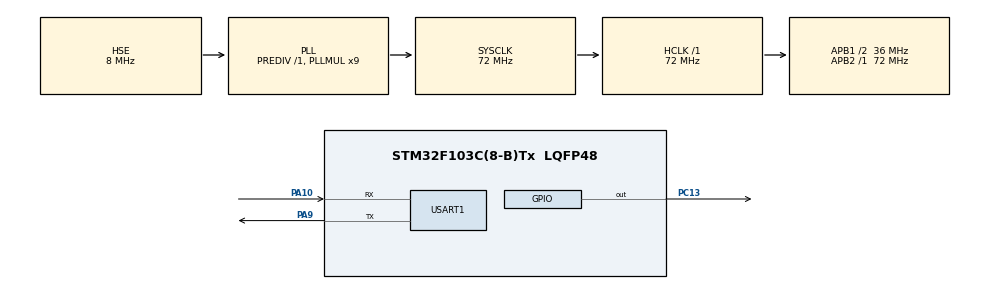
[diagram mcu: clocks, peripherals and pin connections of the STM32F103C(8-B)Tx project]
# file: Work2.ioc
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Mcu.Family=STM32F1
Mcu.Name=STM32F103C(8-B)Tx
Mcu.Package=LQFP48
NVIC.PriorityGroup=NVIC_PRIORITYGROUP_4
NVIC.USART1_IRQn=true\:0\:0\:false\:false\:true\:true\:true\:true
PA10.Mode=Asynchronous
PA10.Signal=USART1_RX
PA13.Mode=Serial_Wire
PA13.Signal=SYS_JTMS-SWDIO
PA14.Mode=Serial_Wire
PA14.Signal=SYS_JTCK-SWCLK
PA9.Mode=Asynchronous
PA9.Signal=USART1_TX
PC13-TAMPER-RTC.PinState=GPIO_PIN_SET
PC13-TAMPER-RTC.Signal=GPIO_Output
PD0-OSC_IN.Mode=HSE-External-Oscillator
PD0-OSC_IN.Signal=RCC_OSC_IN
PD1-OSC_OUT.Mode=HSE-External-Oscillator
PD1-OSC_OUT.Signal=RCC_OSC_OUT
ProjectManager.HeapSize=0x200
ProjectManager.StackSize=0x400
ProjectManager.TargetToolchain=MDK-ARM V5.32
RCC.AHBFreq_Value=72000000
RCC.APB1CLKDivider=RCC_HCLK_DIV2
RCC.APB1Freq_Value=36000000
RCC.APB1TimFreq_Value=72000000
RCC.APB2Freq_Value=72000000
RCC.APB2TimFreq_Value=72000000
RCC.HCLKFreq_Value=72000000
RCC.PLLMUL=RCC_PLL_MUL9
RCC.PLLSourceVirtual=RCC_PLLSOURCE_HSE
RCC.SYSCLKFreq_VALUE=72000000
RCC.SYSCLKSource=RCC_SYSCLKSOURCE_PLLCLK
RCC.USBFreq_Value=72000000
USART1.VirtualMode=VM_ASYNC
board=custom

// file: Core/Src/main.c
/* USER CODE BEGIN Header */
/**
  ******************************************************************************
  * @file           : main.c
  * @brief          : Main program body
  ******************************************************************************
  * @attention
  *
  * Copyright (c) 2024 STMicroelectronics.
  * All rights reserved.
  *
  * This software is licensed under terms that can be found in the LICENSE file
  * in the root directory of this software component.
  * If no LICENSE file comes with this software, it is provided AS-IS.
  *
  ******************************************************************************
  */
/* USER CODE END Header */
#include "main.h"
#include "usart.h"
#include "gpio.h"

/* USER CODE BEGIN Includes */
#include "stdio.h"                     //包含标准输入输出的函数声明
#include "string.h"                   //包含字符串相关的函数声明
/* USER CODE END Includes */

/* USER CODE BEGIN PV */
uint8_t Buffer[50];                  //定义全局数组Buffer
uint8_t RxFlag = 0;                  //定义接收标志位，初值为0
/* USER CODE END PV */

void SystemClock_Config(void);
/* USER CODE BEGIN PFP */
void HAL_UARTEx_RxEventCallback(UART_HandleTypeDef *huart, uint16_t Size)
{
    if (huart == &huart1)       //检查回调函数是否是由huart1（即UART1接口）触发的
    {
        RxFlag = 1;             //如果为1，表示已经接收到数据
        if (strcmp((char *)Buffer , "123\r\n") == 0) //接收到的数据与字符串"123\r\n"进行比较
            {
                HAL_GPIO_WritePin(GPIOC,GPIO_PIN_13,GPIO_PIN_RESET); //点亮PC13
            }
        else if (strcmp((char *)Buffer , "456\r\n") == 0)//接收到的数据与字符串"456\r\n"进行比较
            {
                HAL_GPIO_WritePin(GPIOC,GPIO_PIN_13,GPIO_PIN_SET);      //熄灭PC13
            }
     }
    HAL_UARTEx_ReceiveToIdle_IT(&huart1,Buffer,sizeof(Buffer)); //重新启动UART接收
}
void SendByte(uint8_t Byte)
{
    /* 将字节数据写入数据寄存器，写入后USART自动生成时序波形 */
    HAL_UART_Transmit(&huart1,&Byte,1,1000);
    while(__HAL_UART_GET_FLAG(&huart1,UART_FLAG_TXE) == RESET); //等待发送完成
}
int fputc(int ch ,FILE *f)
{
    SendByte(ch);       //将printf的底层重定向到自己的发送字节函数
    return ch;
}
/* USER CODE END PFP */

int main(void)
{

  /* MCU Configuration--------------------------------------------------------*/

  /* Reset of all peripherals, Initializes the Flash interface and the Systick. */
  HAL_Init();

  /* Configure the system clock */
  SystemClock_Config();

  /* Initialize all configured peripherals */
  MX_GPIO_Init();
  MX_USART1_UART_Init();
  /* USER CODE BEGIN 2 */

  /* 启动了一个中断驱动的UART接收操作*/
  HAL_UARTEx_ReceiveToIdle_IT(&huart1,Buffer,sizeof(Buffer));
  /* USER CODE END 2 */

  /* Infinite loop */
  while (1)
  {

    /* USER CODE BEGIN 3 */
      if (RxFlag == 1)      //如果接收到数据
      {
        RxFlag = 0;         //清空接收标志位
        printf("%s",Buffer); //打印Buffer数组里面的值
      }
  }
  /* USER CODE END 3 */
}

void SystemClock_Config(void)
{
  RCC_OscInitTypeDef RCC_OscInitStruct = {0};
  RCC_ClkInitTypeDef RCC_ClkInitStruct = {0};

  /** Initializes the RCC Oscillators according to the specified parameters
  * in the RCC_OscInitTypeDef structure.
  */
  RCC_OscInitStruct.OscillatorType = RCC_OSCILLATORTYPE_HSE;
  RCC_OscInitStruct.HSEState = RCC_HSE_ON;
  RCC_OscInitStruct.HSEPredivValue = RCC_HSE_PREDIV_DIV1;
  RCC_OscInitStruct.HSIState = RCC_HSI_ON;
  RCC_OscInitStruct.PLL.PLLState = RCC_PLL_ON;
  RCC_OscInitStruct.PLL.PLLSource = RCC_PLLSOURCE_HSE;
  RCC_OscInitStruct.PLL.PLLMUL = RCC_PLL_MUL9;
  if (HAL_RCC_OscConfig(&RCC_OscInitStruct) != HAL_OK)
  {
    Error_Handler();
  }

  /** Initializes the CPU, AHB and APB buses clocks
  */
  RCC_ClkInitStruct.ClockType = RCC_CLOCKTYPE_HCLK|RCC_CLOCKTYPE_SYSCLK
                              |RCC_CLOCKTYPE_PCLK1|RCC_CLOCKTYPE_PCLK2;
  RCC_ClkInitStruct.SYSCLKSource = RCC_SYSCLKSOURCE_PLLCLK;
  RCC_ClkInitStruct.AHBCLKDivider = RCC_SYSCLK_DIV1;
  RCC_ClkInitStruct.APB1CLKDivider = RCC_HCLK_DIV2;
  RCC_ClkInitStruct.APB2CLKDivider = RCC_HCLK_DIV1;

  if (HAL_RCC_ClockConfig(&RCC_ClkInitStruct, FLASH_LATENCY_2) != HAL_OK)
  {
    Error_Handler();
  }
}

void Error_Handler(void)
{
  __disable_irq();
  while (1)
  {
  }
}
